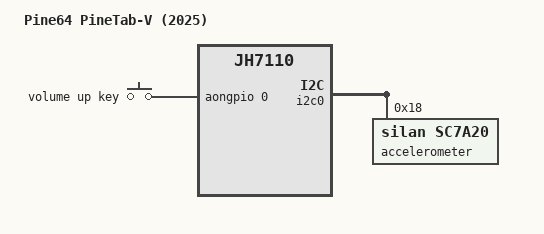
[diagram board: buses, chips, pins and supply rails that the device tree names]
// SPDX-License-Identifier: GPL-2.0 OR MIT
/*
 * Copyright (C) 2022 StarFive Technology Co., Ltd.
 * Copyright (C) 2022 Hal Feng <hal.feng@starfivetech.com>
 * Copyright (C) 2025 Icenowy Zheng <uwu@icenowy.me>
 */

/dts-v1/;
#include "jh7110-pine64-pinetab-v.dtsi"
#include <dt-bindings/input/linux-event-codes.h>

/ {
	model = "Pine64 PineTab-V (2025)";
	compatible = "pine64,pinetab-v-2025", "starfive,jh7110";
};

&gpio_keys {
	key-vol-up {
		label = "volume up key";
		debounce-interval = <10>;
		linux,input-type = <EV_KEY>;
		linux,code = <KEY_VOLUMEUP>;
		gpios = <&aongpio 0 GPIO_ACTIVE_HIGH>;
	};
};

&i2c0 {
	accelerometer@18 {
		compatible = "silan,sc7a20";
		reg = <0x18>;
		mount-matrix =	"0", "0",  "-1",
				"1", "0",  "0",
				"0", "-1", "0";
	};
};
